# Cortex_A35 register map
Vendor: ARM Ltd.; File version: 1.1
Cortex-A35 AArch32 registers
Registers are 32-bit, read-write, no defined reset value unless marked. A register's access mark holds for its fields unless they carry their own. Offsets are from the block's base; lines under a group give offsets from that group; [hi:lo] are bit positions; {n}, {i} and the like mark numbered series; 'fields as' and 'values as' point back to an identical list; <NAME> marks a mode.

## Memory map
0x4A210000 DBG0 size 0xF20
0x4A220000 CTI0 size 0xFF0
0x4A230000 PMU0 size 0xF20
0x4A240000 ETM0 size 0xFF0
0x4A310000 DBG1 size 0xF20
0x4A320000 CTI1 size 0xFF0
0x4A330000 PMU1 size 0xF20
0x4A340000 ETM1 size 0xFF0

## DBG0
Base 0x4A210000
Same registers: DBG1 0x4A310000
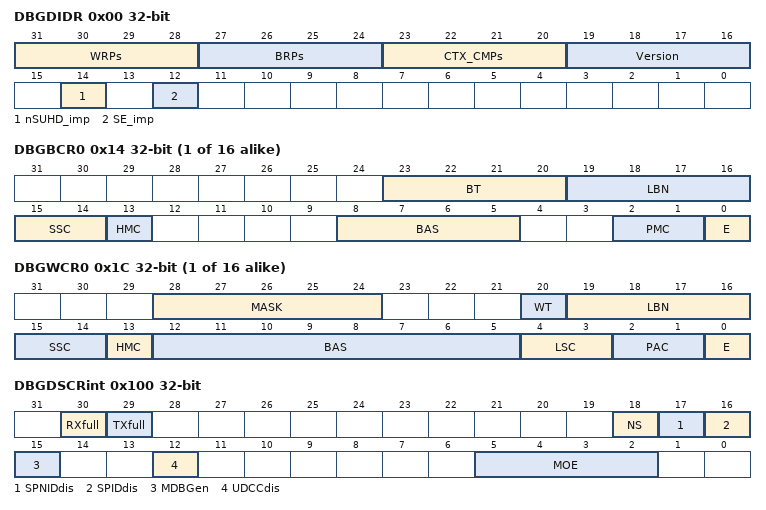
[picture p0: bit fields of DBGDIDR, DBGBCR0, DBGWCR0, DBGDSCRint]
0x00 DBGDIDR
  [31:28] WRPs — Name of field: WRPs
  [27:24] BRPs — Name of field: BRPs
  [23:20] CTX_CMPs — Name of field: CTX_CMPs
  [19:16] Version — Name of field: Version
  [14] nSUHD_imp — Name of field: nSUHD_imp
  [12] SE_imp — Name of field: SE_imp
{0x4+0x100*i} DBGBXVR{i} (i=0..15)
  [7:0] VMID — Name of field: VMID
0x10 DBGOSLAR
  [31:0] OSLA — Name of field: OSLA
{0x14+0x100*i} DBGBCR{i} (i=0..15)
  [23:20] BT — Name of field: BT
  [19:16] LBN — Name of field: LBN
  [15:14] SSC — Name of field: SSC
  [13] HMC — Name of field: HMC
  [8:5] BAS — Name of field: BAS
  [2:1] PMC — Name of field: PMC
  [0] E — Name of field: E
{0x18+0x100*i} DBGWVR{i} (i=0..15)
  [31:2] VA — Name of field: VA
{0x1C+0x100*i} DBGWCR{i} (i=0..15)
  [28:24] MASK — Name of field: MASK
  [20] WT — Name of field: WT
  [19:16] LBN — Name of field: LBN
  [15:14] SSC — Name of field: SSC
  [13] HMC — Name of field: HMC
  [12:5] BAS — Name of field: BAS
  [4:3] LSC — Name of field: LSC
  [2:1] PAC — Name of field: PAC
  [0] E — Name of field: E
0x100 DBGDSCRint
  [30] RXfull — Name of field: RXfull
  [29] TXfull — Name of field: TXfull
  [18] NS — Name of field: NS
  [17] SPNIDdis — Name of field: SPNIDdis
  [16] SPIDdis — Name of field: SPIDdis
  [15] MDBGen — Name of field: MDBGen
  [12] UDCCdis — Name of field: UDCCdis
  [5:2] MOE — Name of field: MOE
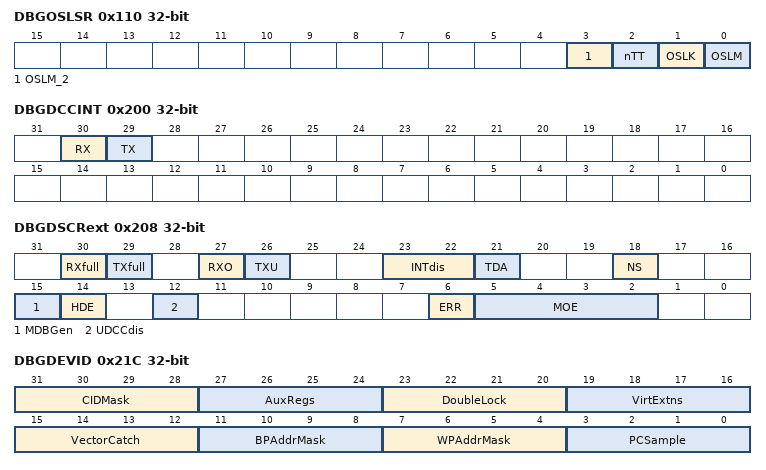
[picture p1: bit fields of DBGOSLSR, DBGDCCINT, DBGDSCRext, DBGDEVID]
0x110 DBGOSLSR
  [3] OSLM_2 — Name of field: OSLM_2
  [2] nTT — Name of field: nTT
  [1] OSLK — Name of field: OSLK
  [0] OSLM — Name of field: OSLM
0x11C DBGDEVID1 (alternate view of DBGWCR1)
  [3:0] PCSROffset — Name of field: PCSROffset
0x200 DBGDCCINT
  [30] RX — Name of field: RX
  [29] TX — Name of field: TX
0x208 DBGDSCRext
  [30] RXfull — Name of field: RXfull
  [29] TXfull — Name of field: TXfull
  [27] RXO — Name of field: RXO
  [26] TXU — Name of field: TXU
  [23:22] INTdis — Name of field: INTdis
  [21] TDA — Name of field: TDA
  [18] NS — Name of field: NS
  [15] MDBGen — Name of field: MDBGen
  [14] HDE — Name of field: HDE
  [12] UDCCdis — Name of field: UDCCdis
  [6] ERR — Name of field: ERR
  [5:2] MOE — Name of field: MOE
0x21C DBGDEVID (alternate view of DBGWCR2)
  [31:28] CIDMask — Name of field: CIDMask
  [27:24] AuxRegs — Name of field: AuxRegs
  [23:20] DoubleLock — Name of field: DoubleLock
  [19:16] VirtExtns — Name of field: VirtExtns
  [15:12] VectorCatch — Name of field: VectorCatch
  [11:8] BPAddrMask — Name of field: BPAddrMask
  [7:4] WPAddrMask — Name of field: WPAddrMask
  [3:0] PCSample — Name of field: PCSample
0x410 DBGPRCR
  [0] CORENPDRQ — Name of field: CORENPDRQ
0x608 DBGOSECCR
  [31:0] EDECCR — Name of field: EDECCR
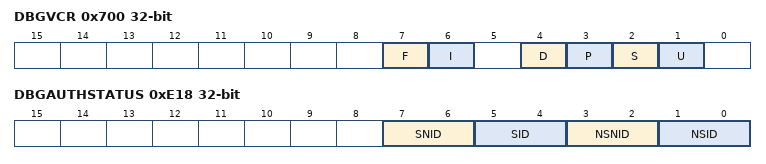
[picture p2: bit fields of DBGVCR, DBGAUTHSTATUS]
0x700 DBGVCR
  [7] F — Name of field: F
  [6] I — Name of field: I
  [4] D — Name of field: D
  [3] P — Name of field: P
  [2] S — Name of field: S
  [1] U — Name of field: U
0x818 DBGCLAIMSET (alternate view of DBGWVR8)
  [7:0] CLAIM — Name of field: CLAIM
0x918 DBGCLAIMCLR (alternate view of DBGWVR9)
  [7:0] CLAIM — Name of field: CLAIM
0xE18 DBGAUTHSTATUS (alternate view of DBGWVR14)
  [7:6] SNID — Name of field: SNID
  [5:4] SID — Name of field: SID
  [3:2] NSNID — Name of field: NSNID
  [1:0] NSID — Name of field: NSID

## CTI0
Base 0x4A220000
Same registers: CTI1 0x4A320000
0x00 CTI_CONTROL
  [0] GLBEN — Name of field: GLBEN
0x10 CTI_INTACK
  [7:0] INTACK — Name of field: INTACK
0x14 CTI_APPSET
  [3:0] APPSET — Name of field: APPSET
0x18 CTI_APPCLEAR
  [3:0] APPCLEAR — Name of field: APPCLEAR
0x1C CTI_APPPULSE
  [3:0] APPULSE — Name of field: APPULSE
{0x20+4i} CTI_INEN{i} (i=0..7)
  [3:0] TRIGINEN — Name of field: TRIGINEN
{0xA0+4i} CTI_OUTEN{i} (i=0..7)
  [3:0] TRIGOUTEN — Name of field: TRIGOUTEN
0x130 CTI_TRIGINSTATUS
  [7:0] TRIGINSTATUS — Name of field: TRIGINSTATUS
0x134 CTI_TRIGOUTSTATUS
  [7:0] TRIGOUTSTATUS — Name of field: TRIGOUTSTATUS
0x138 CTI_CHINSTATUS
  [3:0] CTICHINSTATUS — Name of field: CTICHINSTATUS
0x13C CTI_CHOUTSTATUS
  [3:0] CTICHOUTSTATUS — Name of field: CTICHOUTSTATUS
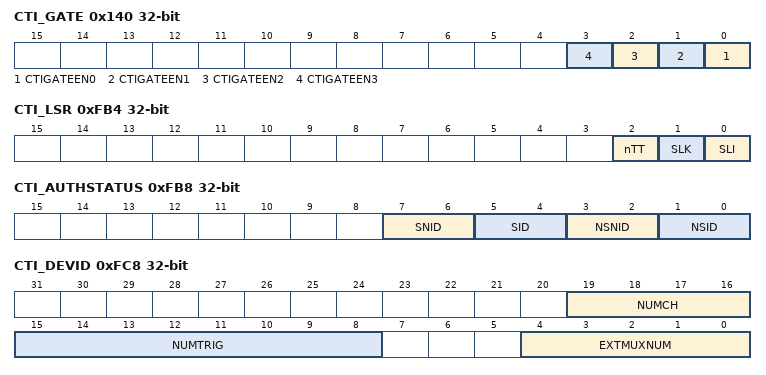
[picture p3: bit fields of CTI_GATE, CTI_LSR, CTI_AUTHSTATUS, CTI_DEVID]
0x140 CTI_GATE
  [n] CTIGATEEN{n} (n=0..3) — Name of field: CTIGATEEN{n}
0x144 CTI_ASICCTL
  [7:0] ASICCTL — Name of field: ASICCTL
0xEDC CTI_ITCHINACK
  [3:0] CTCHINACK — Name of field: CTCHINACK
0xEE0 CTI_ITTRIGINACK
  [7:0] CTTRIGINACK — Name of field: CTTRIGINACK
0xEE4 CTI_ITCHOUT
  [3:0] CTCHOUT — Name of field: CTCHOUT
0xEE8 CTI_ITTRIGOUT
  [7:0] CTTRIGOUT — Name of field: CTTRIGOUT
0xEEC CTI_ITCHOUTACK
  [3:0] CTCHOUTACK — Name of field: CTCHOUTACK
0xEF0 CTI_ITTRIGOUTACK
  [7:0] CTTRIGOUTACK — Name of field: CTTRIGOUTACK
0xEF4 CTI_ITCHIN
  [3:0] CTCHIN — Name of field: CTCHIN
0xEF8 CTI_ITTRIGIN
  [7:0] CTTRIGIN — Name of field: CTTRIGIN
0xF00 CTI_ITCTRL
  [0] IME — Name of field: IME
0xF04 CTI_CLAIMSET
  [3:0] SET — Name of field: SET
0xF08 CTI_CLAIMCLR
  [3:0] CLR — Name of field: CLR
0xFB0 CTI_LAR
  [31:0] KEY — Name of field: KEY
0xFB4 CTI_LSR
  [2] nTT — Name of field: nTT
  [1] SLK — Name of field: SLK
  [0] SLI — Name of field: SLI
0xFB8 CTI_AUTHSTATUS
  [7:6] SNID — Name of field: SNID
  [5:4] SID — Name of field: SID
  [3:2] NSNID — Name of field: NSNID
  [1:0] NSID — Name of field: NSID
0xFC8 CTI_DEVID
  [19:16] NUMCH — Name of field: NUMCH
  [15:8] NUMTRIG — Name of field: NUMTRIG
  [4:0] EXTMUXNUM — Name of field: EXTMUXNUM
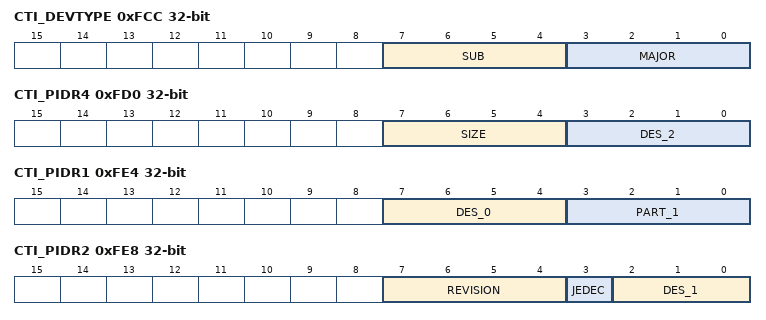
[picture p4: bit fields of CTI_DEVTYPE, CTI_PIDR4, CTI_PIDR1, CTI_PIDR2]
0xFCC CTI_DEVTYPE
  [7:4] SUB — Name of field: SUB
  [3:0] MAJOR — Name of field: MAJOR
0xFD0 CTI_PIDR4
  [7:4] SIZE — Name of field: SIZE
  [3:0] DES_2 — Name of field: DES_2
0xFE0 CTI_PIDR0
  [7:0] PART_0 — Name of field: PART_0
0xFE4 CTI_PIDR1
  [7:4] DES_0 — Name of field: DES_0
  [3:0] PART_1 — Name of field: PART_1
0xFE8 CTI_PIDR2
  [7:4] REVISION — Name of field: REVISION
  [3] JEDEC — Name of field: JEDEC
  [2:0] DES_1 — Name of field: DES_1
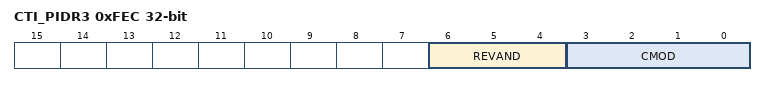
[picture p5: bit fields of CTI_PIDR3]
0xFEC CTI_PIDR3
  [6:4] REVAND — Name of field: REVAND
  [3:0] CMOD — Name of field: CMOD

## Notices in the file
Copyright (c) 2025 STMicroelectronics.
SPDX-License-Identifier: Apache-2.0
Licensed under the Apache License, Version 2.0 (the "License");
you may not use this file except in compliance with the License.
You may obtain a copy of the License at
http://www.apache.org/licenses/LICENSE-2.0
Unless required by applicable law or agreed to in writing, software
distributed under the License is distributed on an "AS IS" BASIS,
WITHOUT WARRANTIES OR CONDITIONS OF ANY KIND, either express or implied.
See the License for the specific language governing permissions and
limitations under the License.
